# STM32L4Q5xx register map
File version: 1.0
Registers are 32-bit, read-write, reset 0x0 unless marked. A register's access mark holds for its fields unless they carry their own. Offsets are from the block's base; [hi:lo] are bit positions; lines under a group give offsets from that group; {n}, {i} and the like mark numbered series.

## FLASH — FLASH Registers
Base 0x40022000
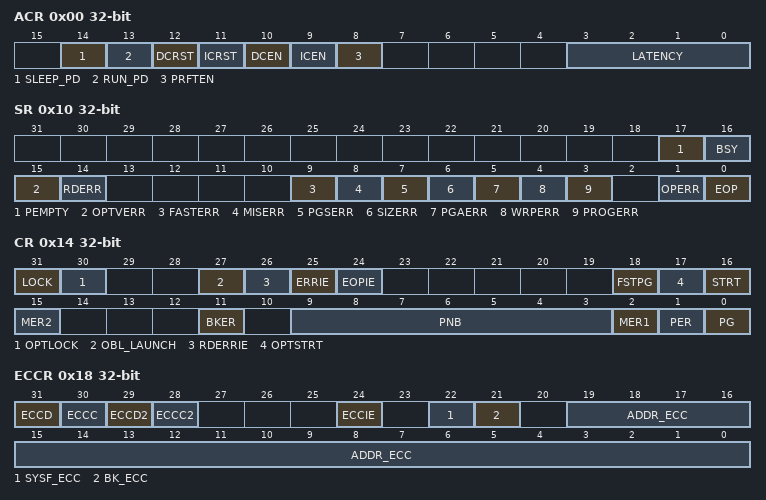
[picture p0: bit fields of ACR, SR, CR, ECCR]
0x00 ACR — FLASH access control register
  [14] SLEEP_PD — Flash power down mode during sleep
  [13] RUN_PD — Flash power down mode during run
  [12] DCRST
  [11] ICRST
  [10] DCEN
  [9] ICEN
  [8] PRFTEN
  [3:0] LATENCY
    0=FLASH Zero wait state; 1=FLASH One wait state; 2=FLASH Two wait states; 3=FLASH Three wait states; 4=FLASH Four wait states; 5=FLASH five wait state; 6=FLASH six wait state; 7=FLASH seven wait states; 8=FLASH eight wait states; 9=FLASH nine wait states; 10=FLASH ten wait states; 11=FLASH eleven wait states; 12=FLASH twelve wait states; 13=FLASH thirteen wait states; 14=FLASH fourteen wait states; 15=FLASH fifteen wait states
0x04 PDKEYR — FLASH power down key register
0x08 KEYR — FLASH key register
0x0C OPTKEYR — FLASH option key register
0x10 SR — FLASH status register
  [17] PEMPTY, [16] BSY, [15] OPTVERR, [14] RDERR, [9] FASTERR, [8] MISERR, [7] PGSERR, [6] SIZERR, [5] PGAERR, [4] WRPERR, [3] PROGERR, [1] OPERR, [0] EOP
0x14 CR — FLASH control register
  [31] LOCK, [30] OPTLOCK, [27] OBL_LAUNCH, [26] RDERRIE, [25] ERRIE, [24] EOPIE, [18] FSTPG, [17] OPTSTRT, [16] STRT, [15] MER2, [11] BKER, [9:3] PNB, [2] MER1, [1] PER, [0] PG
0x18 ECCR — FLASH ECC register
  [31] ECCD, [30] ECCC, [29] ECCD2, [28] ECCC2, [24] ECCIE, [22] SYSF_ECC, [21] BK_ECC, [19:0] ADDR_ECC
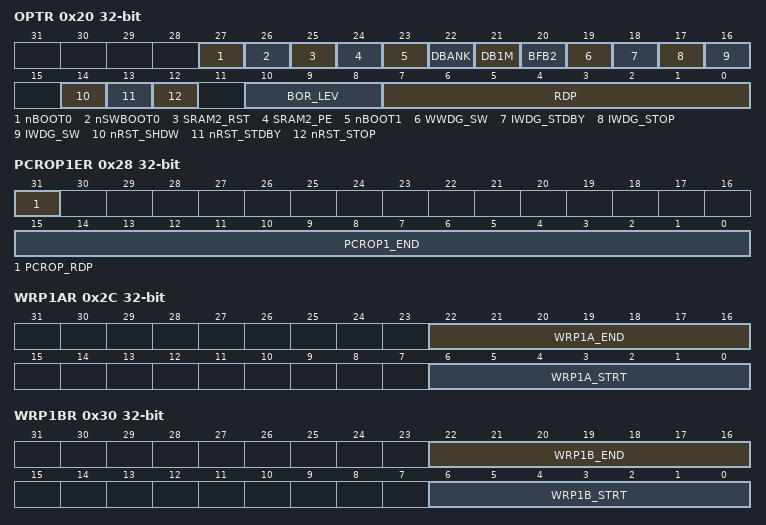
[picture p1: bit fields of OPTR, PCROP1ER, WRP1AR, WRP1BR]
0x20 OPTR — FLASH option register
  [27] nBOOT0, [26] nSWBOOT0, [25] SRAM2_RST, [24] SRAM2_PE, [23] nBOOT1, [22] DBANK, [21] DB1M, [20] BFB2, [19] WWDG_SW, [18] IWDG_STDBY, [17] IWDG_STOP, [16] IWDG_SW, [14] nRST_SHDW, [13] nRST_STDBY, [12] nRST_STOP, [10:8] BOR_LEV, [7:0] RDP
0x24 PCROP1SR — FLASH bank1 PCROP start address register
  [15:0] PCROP1_STRT
0x28 PCROP1ER — FLASH bank1 PCROP end address register
  [31] PCROP_RDP, [15:0] PCROP1_END
0x2C WRP1AR — FLASH bank1 WRP area A address register
  [22:16] WRP1A_END, [6:0] WRP1A_STRT
0x30 WRP1BR — FLASH bank1 WRP area B address register
  [22:16] WRP1B_END, [6:0] WRP1B_STRT
0x44 PCROP2SR — FLASH bank2 PCROP start address register
  [15:0] PCROP2_STRT
0x48 PCROP2ER — FLASH bank2 PCROP end address register
  [15:0] PCROP2_END
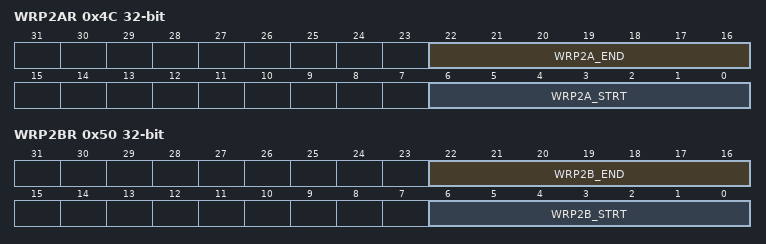
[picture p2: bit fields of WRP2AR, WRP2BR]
0x4C WRP2AR — FLASH bank2 WRP area A address register
  [22:16] WRP2A_END, [6:0] WRP2A_STRT
0x50 WRP2BR — FLASH bank2 WRP area B address register
  [22:16] WRP2B_END, [6:0] WRP2B_STRT
0x130 CFGR — FLASH configuration register
  [0] LVEN — Flash low voltage enable
0x200 DSR — FLASH debug status register

## CRC — CRC calculation unit
Base 0x40023000
0x00 DR — CRC Data register
  [31:0] DR — Data register bits
0x04 IDR — CRC Independent data register
  [31:0] IDR — General-purpose 32-bit data register bits
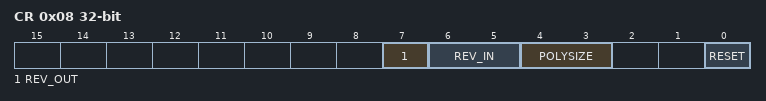
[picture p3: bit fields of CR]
0x08 CR — CRC Control register
  [7] REV_OUT — REV_OUT Reverse Output Data bits
    0=NONE (Output Data bit order not affected); 1=BIT (Output Data bit reversal done by bit)
  [6:5] REV_IN — REV_IN Reverse Input Data bits
    0=NONE (Input Data bit order not affected); 1=BYTE (Input Data bit reversal done by byte); 2=HALFWORD (Input Data bit reversal done by half-word); 3=WORD (Input Data bit reversal done by word)
  [4:3] POLYSIZE — Polynomial size bits
    0=POLYLENGTH_32B (32 bits Polynomial size); 1=POLYLENGTH_16B (16 bits Polynomial size); 2=POLYLENGTH_8B (8 bits Polynomial size); 3=POLYLENGTH_7B (7 bits Polynomial size)
  [0] RESET — RESET the CRC computation unit bit
0x10 INIT — Initial CRC value register
  [31:0] INIT — Initial CRC value bits
0x14 POL — CRC polynomial register
  [31:0] POL — Coefficients of the polynomial

## TSC — Touch Sensing Controller (TSC)
Base 0x40024000
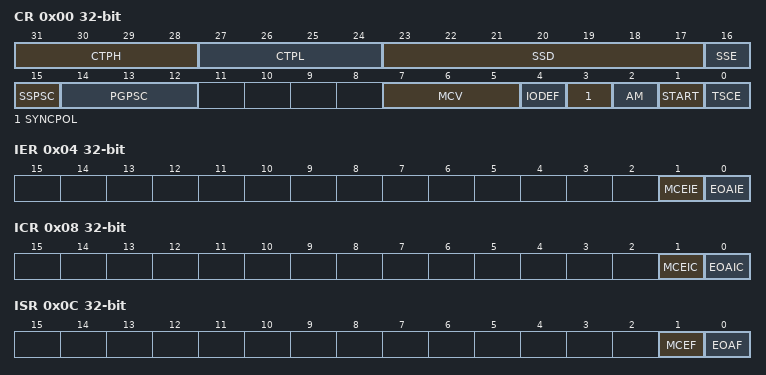
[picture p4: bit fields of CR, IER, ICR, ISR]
0x00 CR — TSC control register
  [31:28] CTPH — CTPH[3:0] bits (Charge Transfer pulse high)
  [27:24] CTPL — CTPL[3:0] bits (Charge Transfer pulse low)
  [23:17] SSD — SSD[6:0] bits (Spread Spectrum Deviation)
  [16] SSE — Spread Spectrum Enable
  [15] SSPSC — Spread Spectrum Prescaler
  [14:12] PGPSC — PGPSC[2:0] bits (Pulse Generator Prescaler)
  [7:5] MCV — MCV[2:0] bits (Max Count Value)
  [4] IODEF — IO default mode
  [3] SYNCPOL — Synchronization pin polarity
  [2] AM — Acquisition mode
  [1] START — Start acquisition
  [0] TSCE — Touch sensing controller enable
0x04 IER — TSC interrupt enable register
  [1] MCEIE — Max count error interrupt enable
  [0] EOAIE — End of acquisition interrupt enable
0x08 ICR — TSC interrupt clear register
  [1] MCEIC — Max count error interrupt clear
  [0] EOAIC — End of acquisition interrupt clear
0x0C ISR — TSC interrupt status register
  [1] MCEF — Max count error flag
  [0] EOAF — End of acquisition flag
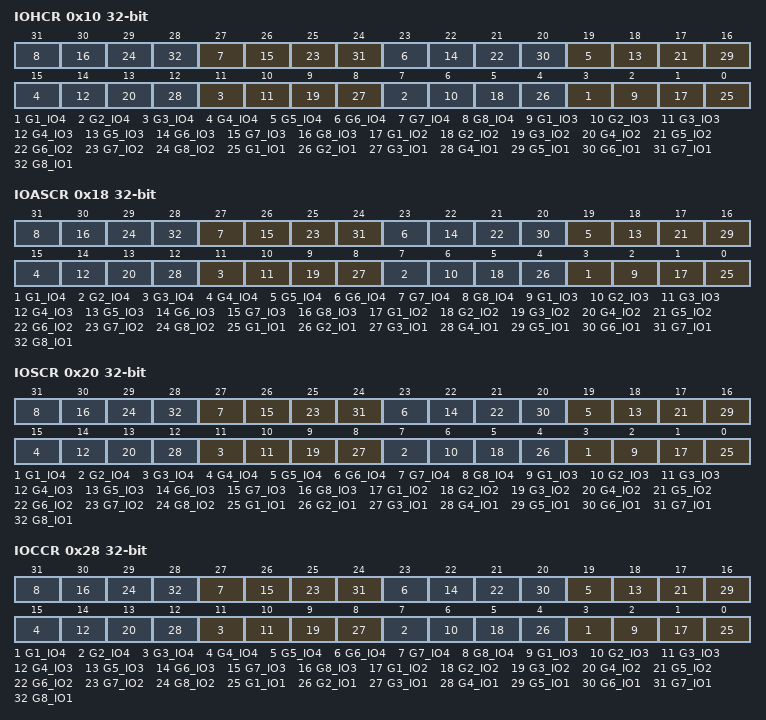
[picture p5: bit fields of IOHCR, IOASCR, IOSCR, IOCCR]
0x10 IOHCR — TSC I/O hysteresis control register
  [4n-1] G{n}_IO4 (n=1..8) — GROUP{n}_IO4 schmitt trigger hysteresis mode
  [4n-2] G{n}_IO3 (n=1..8) — GROUP{n}_IO3 schmitt trigger hysteresis mode
  [4n-3] G{n}_IO2 (n=1..8) — GROUP{n}_IO2 schmitt trigger hysteresis mode
  [4n-4] G{n}_IO1 (n=1..8) — GROUP{n}_IO1 schmitt trigger hysteresis mode
0x18 IOASCR — TSC I/O analog switch control register
  [4n-1] G{n}_IO4 (n=1..8) — GROUP{n}_IO4 analog switch enable
  [4n-2] G{n}_IO3 (n=1..8) — GROUP{n}_IO3 analog switch enable
  [4n-3] G{n}_IO2 (n=1..8) — GROUP{n}_IO2 analog switch enable
  [4n-4] G{n}_IO1 (n=1..8) — GROUP{n}_IO1 analog switch enable
0x20 IOSCR — TSC I/O sampling control register
  [4n-1] G{n}_IO4 (n=1..8) — GROUP{n}_IO4 sampling mode
  [4n-2] G{n}_IO3 (n=1..8) — GROUP{n}_IO3 sampling mode
  [4n-3] G{n}_IO2 (n=1..8) — GROUP{n}_IO2 sampling mode
  [4n-4] G{n}_IO1 (n=1..8) — GROUP{n}_IO1 sampling mode
0x28 IOCCR — TSC I/O channel control register
  [4n-1] G{n}_IO4 (n=1..8) — GROUP{n}_IO4 channel mode
  [4n-2] G{n}_IO3 (n=1..8) — GROUP{n}_IO3 channel mode
  [4n-3] G{n}_IO2 (n=1..8) — GROUP{n}_IO2 channel mode
  [4n-4] G{n}_IO1 (n=1..8) — GROUP{n}_IO1 channel mode
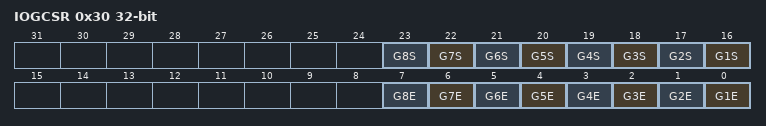
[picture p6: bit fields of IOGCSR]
0x30 IOGCSR — TSC I/O group control status register
  [n+15] G{n}S (n=1..8) — Analog IO GROUP{n} status
  [n-1] G{n}E (n=1..8) — Analog IO GROUP{n} enable
{0x30+4i} IOG{i}CR (i=1..8) — TSC I/O group x counter register
  [13:0] CNT — CNT[13:0] bits (Counter value)
